VERSION ""

NS_ :

BS_:

BU_: EON XXX INTERCEPTOR ANY ACTUATOR SAFETY

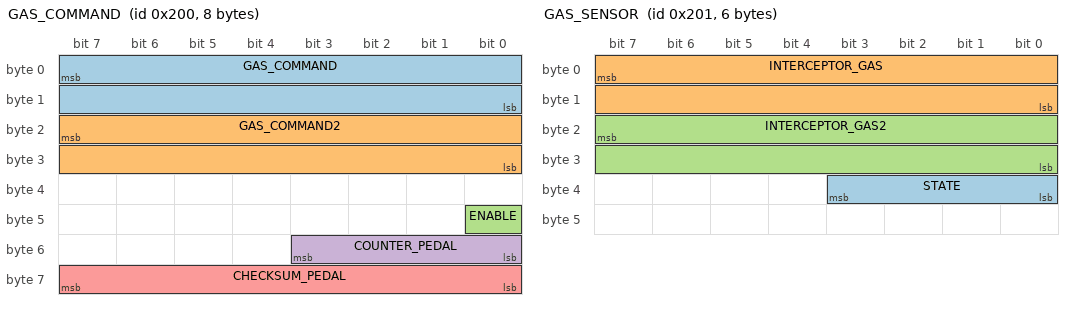
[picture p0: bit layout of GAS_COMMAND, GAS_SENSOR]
BO_ 512 GAS_COMMAND: 8 SAFETY
 SG_ GAS_COMMAND : 7|16@0+ (1,0) [0|1] "" ACTUATOR
 SG_ GAS_COMMAND2 : 23|16@0+ (1,0) [0|1] "" ACTUATOR
 SG_ ENABLE : 40|1@0+ (1,0) [0|1] "" ACTUATOR
 SG_ COUNTER_PEDAL : 51|4@0+ (1,0) [0|15] "" ACTUATOR
 SG_ CHECKSUM_PEDAL : 63|8@0+ (1,0) [0|255] "" ACTUATOR

BO_ 513 GAS_SENSOR: 6 ACTUATOR
 SG_ STATE : 35|4@0+ (1,0) [0|15] "" SAFETY
 SG_ INTERCEPTOR_GAS : 7|16@0+ (0.0007,-0.342) [0|1] "" SAFETY
 SG_ INTERCEPTOR_GAS2 : 23|16@0+ (0.0007,-0.691) [0|1] "" SAFETY

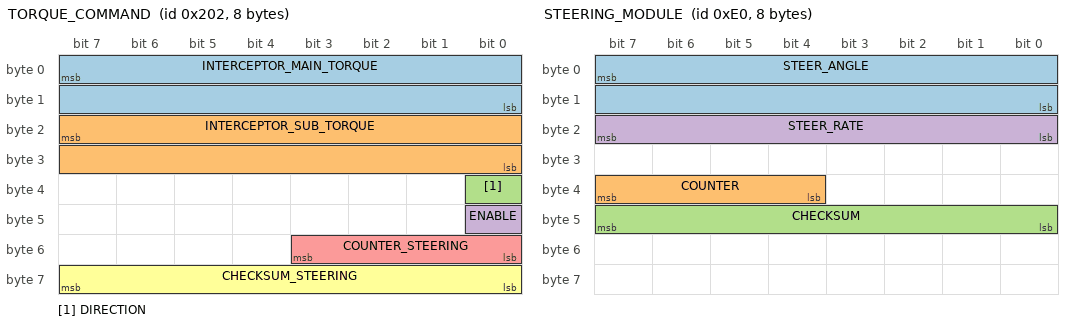
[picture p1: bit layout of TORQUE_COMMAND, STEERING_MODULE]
BO_ 514 TORQUE_COMMAND: 8 SAFETY
 SG_ INTERCEPTOR_MAIN_TORQUE : 7|16@0+ (1,0) [0|1] "" ACTUATOR
 SG_ INTERCEPTOR_SUB_TORQUE : 23|16@0+ (1,0) [0|1] "" ACTUATOR
 SG_ DIRECTION : 32|1@0+ (1,0) [0|1] "" ACTUATOR
 SG_ ENABLE : 40|1@0+ (1,0) [0|1] "" ACTUATOR
 SG_ COUNTER_STEERING : 51|4@0+ (1,0) [0|15] "" ACTUATOR
 SG_ CHECKSUM_STEERING : 63|8@0+ (1,0) [0|255] "" ACTUATOR

BO_ 224 STEERING_MODULE: 8 XXX
 SG_ STEER_ANGLE : 7|16@0- (0.1,0) [0|65535] "" XXX
 SG_ COUNTER : 39|4@0+ (1,0) [0|15] "" XXX
 SG_ CHECKSUM : 47|8@0+ (1,0) [0|255] "" XXX
 SG_ STEER_RATE : 23|8@0+ (1,0) [0|255] "" XXX

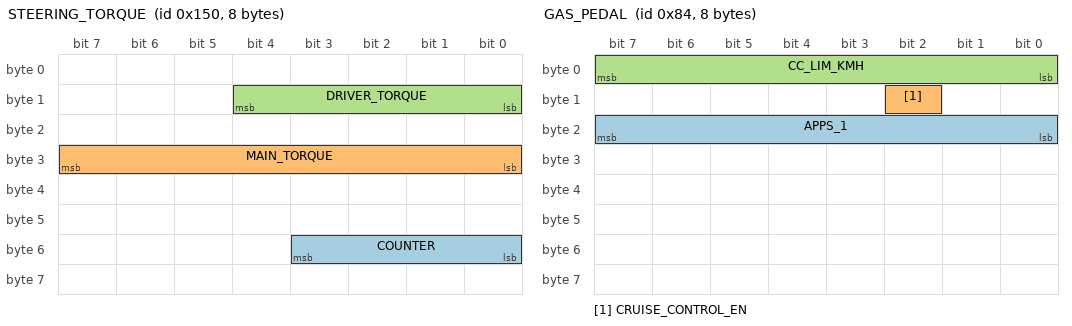
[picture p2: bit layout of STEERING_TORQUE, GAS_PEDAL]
BO_ 336 STEERING_TORQUE: 8 XXX
 SG_ COUNTER : 48|4@1+ (1,0) [0|15] "" XXX
 SG_ MAIN_TORQUE : 24|8@1+ (1,0) [0|255] "" XXX
 SG_ DRIVER_TORQUE : 8|5@1+ (1,0) [0|31] "" XXX

BO_ 291 BRAKE: 8 XXX
 SG_ COUNTER : 48|4@1+ (1,0) [0|15] "" XXX
 SG_ BRAKE_PRESSURE : 39|16@0+ (0.0002,0) [0|65535] "" XXX

BO_ 130 ENGINE: 8 XXX
 SG_ BRAKE_ENGAGED : 35|1@0+ (1,0) [0|1] "" XXX

BO_ 132 GAS_PEDAL: 8 XXX
 SG_ APPS_1 : 23|8@0+ (0.004,0) [0|255] "" XXX
 SG_ CRUISE_CONTROL_EN : 10|1@0+ (1,0) [0|1] "" XXX
 SG_ CC_LIM_KMH : 7|8@0+ (1,0) [0|255] "" XXX

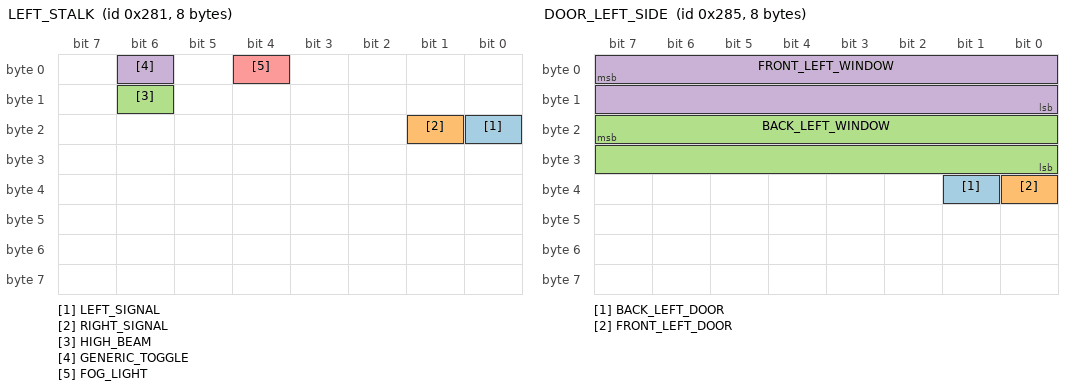
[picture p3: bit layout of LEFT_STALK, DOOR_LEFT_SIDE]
BO_ 641 LEFT_STALK: 8 XXX
 SG_ LEFT_SIGNAL : 16|1@0+ (1,0) [0|1] "" XXX
 SG_ RIGHT_SIGNAL : 17|1@0+ (1,0) [0|1] "" XXX
 SG_ HIGH_BEAM : 14|1@0+ (1,0) [0|1] "" XXX
 SG_ GENERIC_TOGGLE : 6|1@0+ (1,0) [0|511] "" XXX
 SG_ FOG_LIGHT : 4|1@0+ (1,0) [0|1] "" XXX

BO_ 417 ACC_CMD: 8 XXX
 SG_ CRUISE_ENABLE : 37|1@0+ (1,0) [0|1] "" XXX
 SG_ COUNTER : 40|4@1+ (1,0) [0|15] "" XXX

BO_ 645 DOOR_LEFT_SIDE: 8 XXX
 SG_ BACK_LEFT_DOOR : 33|1@0+ (1,0) [0|511] "" XXX
 SG_ FRONT_LEFT_DOOR : 32|1@0+ (1,0) [0|511] "" XXX
 SG_ BACK_LEFT_WINDOW : 23|16@0+ (0.000019422,0) [0|65535] "" XXX
 SG_ FRONT_LEFT_WINDOW : 7|16@0+ (1,0) [0|65535] "" XXX

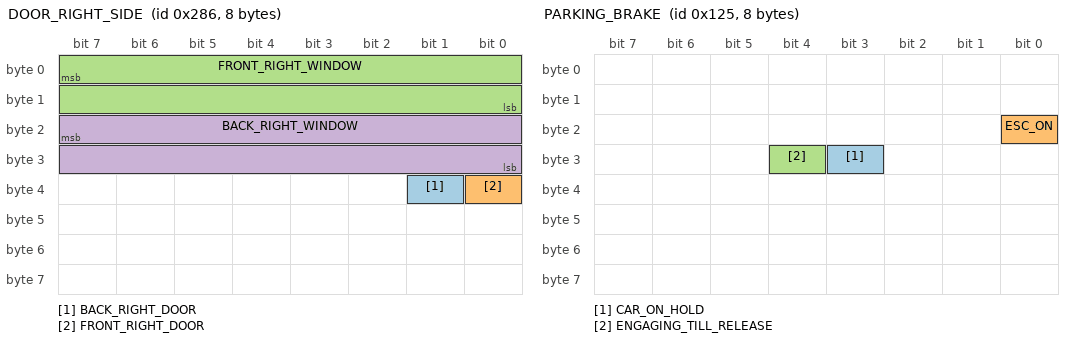
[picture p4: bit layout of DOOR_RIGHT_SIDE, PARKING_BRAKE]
BO_ 646 DOOR_RIGHT_SIDE: 8 XXX
 SG_ BACK_RIGHT_DOOR : 33|1@0+ (1,0) [0|1] "" XXX
 SG_ FRONT_RIGHT_DOOR : 32|1@0+ (1,0) [0|511] "" XXX
 SG_ FRONT_RIGHT_WINDOW : 7|16@0+ (0.000019422,0) [0|65535] "" XXX
 SG_ BACK_RIGHT_WINDOW : 23|16@0+ (0.000019422,0) [0|65535] "" XXX

BO_ 896 SEATBELTS: 8 XXX
 SG_ RIGHT_SIDE_SEATBELT_ACTIVE_LOW : 0|1@0+ (1,0) [0|1] "" XXX
 SG_ LEFT_SIDE_SEATBELT_ACTIVE_LOW : 1|1@0+ (1,0) [0|1] "" XXX

BO_ 293 PARKING_BRAKE: 8 XXX
 SG_ CAR_ON_HOLD : 27|1@0+ (1,0) [0|1] "" XXX
 SG_ ESC_ON : 16|1@0+ (1,0) [0|1] "" XXX
 SG_ ENGAGING_TILL_RELEASE : 28|1@0+ (1,0) [0|1] "" XXX

BO_ 275 TRANSMISSION: 8 XXX
 SG_ GEAR : 39|4@0+ (1,0) [0|255] "" XXX

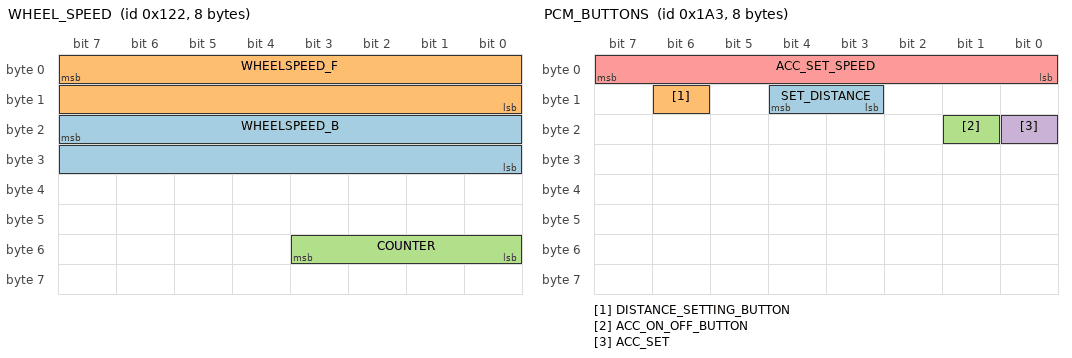
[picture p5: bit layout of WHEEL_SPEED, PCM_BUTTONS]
BO_ 290 WHEEL_SPEED: 8 XXX
 SG_ WHEELSPEED_B : 23|16@0+ (0.0070,0) [0|65535] "" XXX
 SG_ WHEELSPEED_F : 7|16@0+ (0.0070,0) [0|65535] "" XXX
 SG_ COUNTER : 48|4@1+ (1,0) [0|15] "" XXX

BO_ 419 PCM_BUTTONS: 8 XXX
 SG_ SET_DISTANCE : 12|2@0+ (1,0) [0|3] "" XXX
 SG_ DISTANCE_SETTING_BUTTON : 14|1@0+ (1,0) [0|1] "" XXX
 SG_ ACC_ON_OFF_BUTTON : 17|1@0+ (1,0) [0|1] "" XXX
 SG_ ACC_SET : 16|1@0+ (1,0) [0|1] "" XXX
 SG_ ACC_SET_SPEED : 7|8@0+ (1,0) [0|255] "" XXX

BO_ 676 POWER_MODE: 8 XXX
 SG_ MODE : 15|2@0+ (1,0) [0|3] "" XXX

BO_ 753 AIRCON: 8 XXX
 SG_ AC_ON : 2|1@0+ (1,0) [0|511] "" XXX

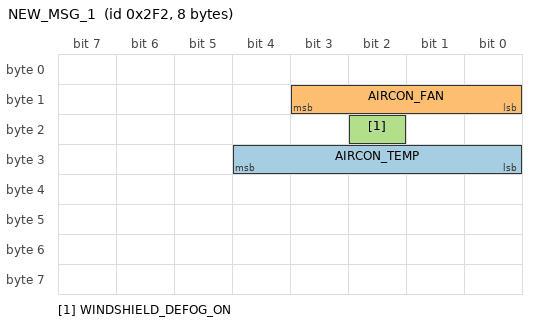
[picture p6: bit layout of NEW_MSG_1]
BO_ 754 NEW_MSG_1: 8 XXX
 SG_ AIRCON_TEMP : 24|5@1+ (1,0) [0|15] "" XXX
 SG_ AIRCON_FAN : 8|4@1+ (1,0) [0|15] "" XXX
 SG_ WINDSHIELD_DEFOG_ON : 18|1@0+ (1,0) [0|1] "" XXX

BO_ 528 WHEELSPEED: 8 XXX
 SG_ WHEELSPEED_FRONT : 7|16@0+ (0.0088,-0.0704) [0|16777215] "" XXX
 SG_ WHEELSPEED_BACK : 23|16@0+ (0.0011,-0.0704) [0|65535] "" XXX

VAL_ 676 MODE 2 "NORMAL" 1 "SPORT" 0 "ECO" ;
VAL_ 275 GEAR 15 "D" 14 "D" 13 "D" 12 "D" 11 "R" 10 "P" 9 "D" 8 "D" 7 "D" 6 "D" 5 "D" 4 "D" 3 "D" 2 "D" 1 "D" 0 "N" ;
VAL_ 419 SET_DISTANCE 3 "3BAR" 2 "2BAR" 1 "1BAR" ;
